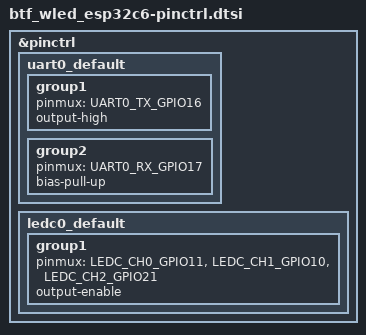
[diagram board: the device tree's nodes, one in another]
/*
 * SPDX-License-Identifier: Apache-2.0
 *
 * Same PCB as btf_wled_esp32, with the ESP32-C6-WROOM-1-N8 soldered onto
 * the WROOM-32E footprint (the 28 side castellations align pad-for-pad;
 * the 32E's 10 bottom pads are left open). The pads therefore keep their
 * old nets but carry new GPIO numbers:
 *
 *   silk CH1 (pad 12, was GPIO27) -> GPIO11
 *   silk CH2 (pad 11, was GPIO26) -> GPIO10
 *   silk CH3                      -> GPIO21  <-- rewired, see below
 *   button S1 (pad 25, was GPIO0) -> GPIO9   (the C6's boot pin: same
 *                                             hold-low-for-download semantics)
 *   UART0    (pads 34/35)         -> RXD=GPIO17, TXD=GPIO16
 *
 * GPIO8 strap + CH3 rework (as-built, HW-verified at bring-up 2026-07-18):
 * the C6 boot strap needs GPIO8=1 while GPIO9 is held low through reset
 * (datasheet Table 4-3), but GPIO8 (pad 10, old IO25/CH3 net) has no
 * internal pull and this pad drives a 74HC245 buffer input. A 10k pull-up
 * alone only reached ~1.7V (the '245 net loaded it down -- no discrete
 * pull-down present), so download-mode entry was unreliable. Fix: CUT the
 * pad-10 trace to the '245 -- GPIO8 then sits at a clean 3.3V and carries
 * only the strap pull-up (drives nothing). That severed silk CH3, so CH3
 * was rewired by jumpering footprint pad 19 (IO21, previously NC) to the
 * CH3 buffer input -- hence LEDC ch2 is on GPIO21. Normal SPI boot ignores
 * GPIO8, and the app may drive it freely after the strap-hold window.
 *
 * Channel numbering matches the classic board: LEDC ch0=CH1(cool),
 * ch1=CH2(warm), ch2=CH3, so the app's LEDCTRL_CH_* defaults hold.
 */

#include <zephyr/dt-bindings/pinctrl/esp-pinctrl-common.h>
#include <zephyr/dt-bindings/pinctrl/esp32c6-pinctrl.h>
#include <zephyr/dt-bindings/pinctrl/esp32c6-gpio-sigmap.h>

&pinctrl {
	uart0_default: uart0_default {
		group1 {
			pinmux = <UART0_TX_GPIO16>;
			output-high;
		};

		group2 {
			pinmux = <UART0_RX_GPIO17>;
			bias-pull-up;
		};
	};

	ledc0_default: ledc0_default {
		group1 {
			pinmux = <LEDC_CH0_GPIO11>,
				 <LEDC_CH1_GPIO10>,
				 <LEDC_CH2_GPIO21>;
			output-enable;
		};
	};
};
